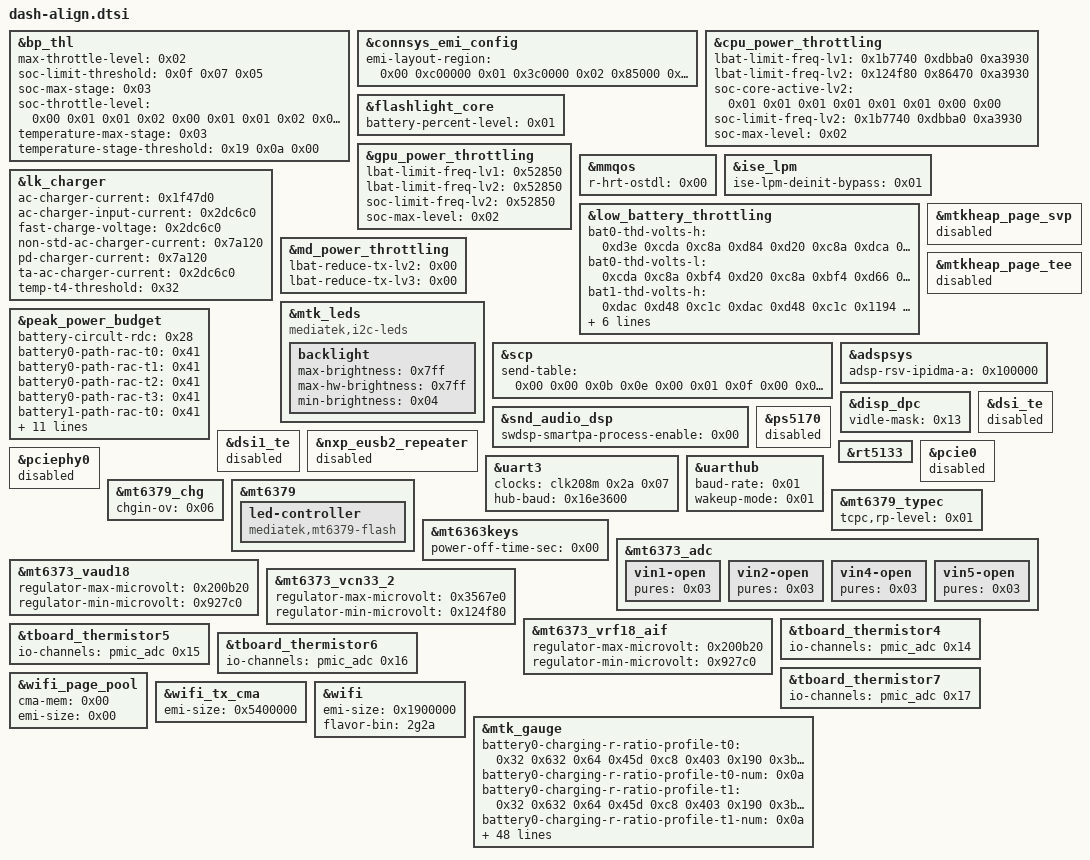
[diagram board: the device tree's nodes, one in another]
// SPDX-License-Identifier: (GPL-2.0 OR MIT)
/*
 * Pin the merged dash dtb to the values of the dtb the device is
 * proven to boot with (stock base, dtb/01_dtbdump_MT6991.dtb).
 * The xiaomi base and the reconstructed overlay carry the tuning of
 * a newer stock release; the drifting values below are aligned back.
 * Kept from the source: the dash-specific battery table, the newer
 * display event tables (supersets), and the connectivity/DRAM
 * identity (mt6639 wifi, current dram flavor).
 */

&bp_thl {
	max-throttle-level = <0x02>;
	soc-limit-threshold = <0x0f 0x07 0x05>;
	soc-max-stage = <0x03>;
	soc-throttle-level = <0x00 0x01 0x01 0x02 0x00 0x01 0x01 0x02 0x00 0x01 0x01 0x02 0x00 0x01 0x02 0x02>;
	temperature-max-stage = <0x03>;
	temperature-stage-threshold = <0x19 0x0a 0x00>;
};

&connsys_emi_config {
	emi-layout-region = <0x00 0xc00000 0x01 0x3c0000 0x02 0x85000 0x03 0x4b000 0x04 0x12000 0x05 0xe000 0x06 0x40000 0x07 0x140000 0x08 0x2fa000 0x09 0xd6000 0x0a 0xa0000 0x0b 0x1900000>;
};

&cpu_power_throttling {
	lbat-limit-freq-lv1 = <0x1b7740 0xdbba0 0xa3930>;
	lbat-limit-freq-lv2 = <0x124f80 0x86470 0xa3930>;
	soc-core-active-lv2 = <0x01 0x01 0x01 0x01 0x01 0x01 0x00 0x00>;
	soc-limit-freq-lv2 = <0x1b7740 0xdbba0 0xa3930>;
	soc-max-level = <0x02>;
};

&flashlight_core {
	battery-percent-level = <0x01>;
};

&gpu_power_throttling {
	lbat-limit-freq-lv1 = <0x52850>;
	lbat-limit-freq-lv2 = <0x52850>;
	soc-limit-freq-lv2 = <0x52850>;
	soc-max-level = <0x02>;
};

&mmqos {
	r-hrt-ostdl = <0x00>;
};

&ise_lpm {
	ise-lpm-deinit-bypass = <0x01>;
};

&lk_charger {
	ac-charger-current = <0x1f47d0>;
	ac-charger-input-current = <0x2dc6c0>;
	fast-charge-voltage = <0x2dc6c0>;
	non-std-ac-charger-current = <0x7a120>;
	pd-charger-current = <0x7a120>;
	ta-ac-charger-current = <0x2dc6c0>;
	temp-t4-threshold = <0x32>;
};

&low_battery_throttling {
	bat0-thd-volts-h = <0xd3e 0xcda 0xc8a 0xd84 0xd20 0xc8a 0xdca 0xd66 0xc8a 0xe38 0xdd4 0xc8a>;
	bat0-thd-volts-l = <0xcda 0xc8a 0xbf4 0xd20 0xc8a 0xbf4 0xd66 0xc8a 0xbf4 0xdd4 0xc8a 0xbf4>;
	bat1-thd-volts-h = <0xdac 0xd48 0xc1c 0xdac 0xd48 0xc1c 0x1194 0x1130 0xd48 0x1388 0x1324 0x12c0>;
	bat1-thd-volts-l = <0xd48 0xc1c 0xb54 0xd48 0xc1c 0xb54 0x1130 0xd48 0xc1c 0x1324 0x12c0 0x1130>;
	lvsys-thd-volt-h = <0xc1c>;
	temperature-stage-threshold = <0x19 0x0a 0x00>;
	throttle-level = <0x00 0x01 0x02 0x03 0x00 0x01 0x02 0x03 0x00 0x01 0x02 0x03 0x00 0x01 0x02 0x03>;
};

&md_power_throttling {
	lbat-reduce-tx-lv2 = <0x00>;
	lbat-reduce-tx-lv3 = <0x00>;
};

&mtk_leds {
	compatible = "mediatek,i2c-leds";
	backlight {
		max-brightness = <0x7ff>;
		max-hw-brightness = <0x7ff>;
		min-brightness = <0x04>;
	};
};

&mtkheap_page_svp {
	status = "disabled";
};

&mtkheap_page_tee {
	status = "disabled";
};

&peak_power_budget {
	battery-circult-rdc = <0x28>;
	battery0-path-rac-t0 = <0x41>;
	battery0-path-rac-t1 = <0x41>;
	battery0-path-rac-t2 = <0x41>;
	battery0-path-rac-t3 = <0x41>;
	battery1-path-rac-t0 = <0x41>;
	battery1-path-rac-t1 = <0x41>;
	battery1-path-rac-t2 = <0x41>;
	battery1-path-rac-t3 = <0x41>;
	battery2-path-rac-t0 = <0x41>;
	battery2-path-rac-t1 = <0x41>;
	battery2-path-rac-t2 = <0x41>;
	battery2-path-rac-t3 = <0x41>;
	soc-hpt-ctrl-lv2 = <0x00>;
	soc-max-level = <0x02>;
	system-uvlo = <0xa32>;
	temperature-threshold = <0x19 0x0a 0x00>;
};

&scp {
	send-table = <0x00 0x00 0x0b 0x0e 0x00 0x01 0x0f 0x00 0x02 0x10 0x00 0x01 0x12 0x00 0x02 0x2e 0x00 0x01 0x11 0x01 0x06 0x1d 0x01 0x10 0x1f 0x01 0x07 0x34 0x01 0x0a 0x04 0x02 0x01 0x05 0x02 0x02 0x06 0x02 0x01 0x21 0x02 0x10 0x36 0x02 0x04 0x03 0x03 0x04 0x25 0x03 0x01 0x1a 0x03 0x09 0x23 0x03 0x02 0x2d 0x03 0x01 0x2f 0x03 0x02 0x30 0x03 0x02 0x27 0x04 0x04 0x2b 0x04 0x04>;
};

&snd_audio_dsp {
	swdsp-smartpa-process-enable = <0x00>;
};

&adspsys {
	adsp-rsv-ipidma-a = <0x100000>;
};

&disp_dpc {
	vidle-mask = <0x13>;
};

&dsi_te {
	status = "disabled";
};

&dsi1_te {
	status = "disabled";
};

&nxp_eusb2_repeater {
	status = "disabled";
};

&ps5170 {
	status = "disabled";
};

&rt5133 {
	status = "ok";
};

&pcie0 {
	status = "disabled";
};

&pciephy0 {
	status = "disabled";
};

&uart3 {
	clocks = <&clk208m 0x2a 0x07>;
	hub-baud = <0x16e3600>;
};

&uarthub {
	baud-rate = <0x01>;
	wakeup-mode = <0x01>;
};

&mt6379_chg {
	chgin-ov = <0x06>;
};

&mt6379 {
	led-controller {
		compatible = "mediatek,mt6379-flash";
	};
};

&mt6379_typec {
	tcpc,rp-level = <0x01>;
};

&mt6363keys {
	power-off-time-sec = <0x00>;
};

&mt6373_adc {
	vin1-open {
		pures = <0x03>;
	};
	vin2-open {
		pures = <0x03>;
	};
	vin4-open {
		pures = <0x03>;
	};
	vin5-open {
		pures = <0x03>;
	};
};

&mt6373_vaud18 {
	regulator-max-microvolt = <0x200b20>;
	regulator-min-microvolt = <0x927c0>;
};

&mt6373_vcn33_2 {
	regulator-max-microvolt = <0x3567e0>;
	regulator-min-microvolt = <0x124f80>;
};

&mt6373_vrf18_aif {
	regulator-max-microvolt = <0x200b20>;
	regulator-min-microvolt = <0x927c0>;
};

&tboard_thermistor4 {
	io-channels = <&pmic_adc 0x14>;
};

&tboard_thermistor5 {
	io-channels = <&pmic_adc 0x15>;
};

&tboard_thermistor6 {
	io-channels = <&pmic_adc 0x16>;
};

&tboard_thermistor7 {
	io-channels = <&pmic_adc 0x17>;
};

&wifi_page_pool {
	cma-mem = <0x00>;
	emi-size = <0x00>;
};

&wifi_tx_cma {
	emi-size = <0x5400000>;
};

&wifi {
	emi-size = <0x1900000>;
	flavor-bin = "2g2a";
};

/* Battery: align the fuel gauge table with the proven dtb. The newer
 * dash table made the gauge report 0% (ui_soc=0) and the device shuts
 * down right after the logo. */
&mtk_gauge {
	battery0-charging-r-ratio-profile-t0 = <0x32 0x632 0x64 0x45d 0xc8 0x403 0x190 0x3bb 0x258 0x3a3 0x320 0x385 0x3e8 0x35d 0x5dc 0x336 0x7d0 0x332 0x9c4 0x2db>;
	battery0-charging-r-ratio-profile-t0-num = <0x0a>;
	battery0-charging-r-ratio-profile-t1 = <0x32 0x632 0x64 0x45d 0xc8 0x403 0x190 0x3bb 0x258 0x3a3 0x320 0x385 0x3e8 0x35d 0x5dc 0x336 0x7d0 0x332 0x9c4 0x2db>;
	battery0-charging-r-ratio-profile-t1-num = <0x0a>;
	battery0-charging-r-ratio-profile-t2 = <0x32 0x632 0x64 0x45d 0xc8 0x403 0x190 0x3bb 0x258 0x3a3 0x320 0x385 0x3e8 0x35d 0x5dc 0x336 0x7d0 0x332 0x9c4 0x2db>;
	battery0-charging-r-ratio-profile-t2-num = <0x0a>;
	battery0-charging-r-ratio-profile-t3 = <0x32 0x632 0x64 0x45d 0xc8 0x403 0x190 0x3bb 0x258 0x3a3 0x320 0x385 0x3e8 0x35d 0x5dc 0x336 0x7d0 0x332 0x9c4 0x2db>;
	battery0-charging-r-ratio-profile-t3-num = <0x0a>;
	battery0-charging-r-ratio-profile-t4 = <0x32 0x632 0x64 0x45d 0xc8 0x403 0x190 0x3bb 0x258 0x3a3 0x320 0x385 0x3e8 0x35d 0x5dc 0x336 0x7d0 0x332 0x9c4 0x2db>;
	battery0-charging-r-ratio-profile-t4-num = <0x0a>;
	battery0-profile-t0 = <0x00 0xa956 0x96 0x17c 0xa8f7 0x96 0x2f8 0xa886 0x96 0x473 0xa82e 0xd6 0x5ef 0xa790 0x69 0x76b 0xa738 0x106 0x8e7 0xa6bd 0xff 0xa63 0xa656 0xe1 0xbde 0xa5e9 0xc3 0xd5a 0xa578 0xaf 0xed6 0xa510 0xc8 0x1052 0xa4a7 0xec 0x11ce 0xa427 0xf0 0x1349 0xa3a8 0xe1 0x14c5 0xa348 0xda 0x1641 0xa2c1 0xd4 0x17bd 0xa27f 0xfa 0x1939 0xa20f 0xec 0x1ab4 0xa180 0x9f 0x1c30 0xa13c 0xfe 0x1dac 0xa0dd 0x15d 0x1f28 0xa046 0xe9 0x20a4 0xa007 0x10d 0x221f 0x9fb5 0x113 0x239b 0x9f20 0xc4 0x2517 0x9edf 0xf9 0x2693 0x9e8f 0x169 0x280f 0x9e37 0x150 0x298a 0x9dd6 0x167 0x2b06 0x9d72 0x183 0x2c82 0x9d05 0x13a 0x2dfe 0x9c9b 0x11b 0x2f7a 0x9c55 0x175 0x30f5 0x9c11 0x1c2 0x3271 0x9ba6 0x1a6 0x33ed 0x9b2d 0x14d 0x3569 0x9aa2 0x125 0x36e5 0x9a24 0x16a 0x3860 0x9999 0x107 0x39dc 0x9932 0x83 0x3b58 0x9903 0x141 0x3cd4 0x98c1 0xd1 0x3e50 0x987e 0xf4 0x3fcb 0x983c 0x123 0x4147 0x9801 0xf2 0x42c3 0x97ab 0x98 0x443f 0x9789 0xe3 0x45bb 0x9760 0xf4 0x4736 0x9727 0x11b 0x48b2 0x96df 0xe9 0x4a2e 0x96a1 0x96 0x4baa 0x9683 0xb8 0x4d25 0x9664 0xe1 0x4ea1 0x962a 0xc7 0x501d 0x95f6 0xd9 0x5199 0x95e7 0x158 0x5315 0x95aa 0xfa 0x5490 0x956b 0x10c 0x560c 0x956b 0x161 0x5788 0x951a 0x9c 0x5904 0x9524 0x112 0x5a80 0x94d8 0xcc 0x5bfb 0x94b9 0xc8 0x5d77 0x94be 0x171 0x5ef3 0x9471 0xde 0x606f 0x943e 0x11e 0x61eb 0x93e8 0xef 0x6366 0x93b3 0x128 0x64e2 0x936d 0xd9 0x665e 0x9339 0xc1 0x67da 0x9304 0xb1 0x6956 0x92d2 0xd2 0x6ad1 0x92a9 0x11a 0x6c4d 0x9261 0xc8 0x6dc9 0x9234 0xf3 0x6f45 0x9216 0xe1 0x70c1 0x91ff 0xd3 0x723c 0x91b7 0xa7 0x73b8 0x9185 0x102 0x7534 0x913b 0x51 0x76b0 0x9115 0xf7 0x782c 0x90e5 0xcb 0x79a7 0x90b6 0x14d 0x7b23 0x9044 0xb7 0x7c9f 0x9026 0x10b 0x7e1b 0x9015 0x13e 0x7f97 0x9009 0x156 0x8112 0x9000 0x11f 0x828e 0x8ff6 0x109 0x840a 0x8fcd 0x120 0x8586 0x8fa2 0xfc 0x8702 0x8f53 0xfe 0x887d 0x8e6c 0x13c 0x89f9 0x8cfc 0x12c 0x8b75 0x8b33 0x117 0x8cf1 0x88b9 0x11a 0x8e6d 0x8572 0x1d7 0x8fe8 0x7fd4 0x3e3 0x9164 0x7472 0x17b7 0x92e0 0x6e0a 0x327d>;
	battery0-profile-t0-col = <0x03>;
	battery0-profile-t0-num = <0x64>;
	battery0-profile-t1 = <0x00 0xa92e 0x1db 0x17c 0xa8a0 0x1db 0x2f8 0xa835 0x1db 0x473 0xa7cd 0x1f0 0x5ef 0xa74c 0x1cc 0x76b 0xa6cf 0x19d 0x8e7 0xa668 0x1c4 0xa63 0xa603 0x1eb 0xbde 0xa583 0x1aa 0xd5a 0xa520 0x1e4 0xed6 0xa4b6 0x20e 0x1052 0xa442 0x1fc 0x11ce 0xa3e1 0x21c 0x1349 0xa36b 0x216 0x14c5 0xa2f3 0x201 0x1641 0xa281 0x1b5 0x17bd 0xa211 0x1d6 0x1939 0xa1aa 0x1cd 0x1ab4 0xa14c 0x20f 0x1c30 0xa0f6 0x225 0x1dac 0xa08d 0x20d 0x1f28 0xa01b 0x23c 0x20a4 0x9fbb 0x23f 0x221f 0x9f5c 0x269 0x239b 0x9ef5 0x20f 0x2517 0x9e86 0x219 0x2693 0x9e28 0x248 0x280f 0x9dd3 0x258 0x298a 0x9d83 0x275 0x2b06 0x9d2c 0x28a 0x2c82 0x9cd7 0x2a2 0x2dfe 0x9c7e 0x2b1 0x2f7a 0x9c1a 0x2c0 0x30f5 0x9bb4 0x2dd 0x3271 0x9b42 0x2ae 0x33ed 0x9ac5 0x279 0x3569 0x9a2c 0x23f 0x36e5 0x99bc 0x235 0x3860 0x9956 0x1f6 0x39dc 0x990a 0x20e 0x3b58 0x98c7 0x225 0x3cd4 0x9872 0x1b2 0x3e50 0x981d 0x1a9 0x3fcb 0x97e0 0x1a9 0x4147 0x97a0 0x1bc 0x42c3 0x976c 0x1b0 0x443f 0x973c 0x1cb 0x45bb 0x970d 0x1cb 0x4736 0x96e3 0x1d0 0x48b2 0x96b2 0x1ce 0x4a2e 0x9688 0x1f1 0x4baa 0x965a 0x206 0x4d25 0x9627 0x1f7 0x4ea1 0x9607 0x23e 0x501d 0x95e1 0x24f 0x5199 0x95b9 0x1ff 0x5315 0x9588 0x219 0x5490 0x9555 0x1e7 0x560c 0x9548 0x23a 0x5788 0x9519 0x1f3 0x5904 0x94ea 0x1dc 0x5a80 0x94f1 0x265 0x5bfb 0x94be 0x25b 0x5d77 0x94ae 0x281 0x5ef3 0x9486 0x277 0x606f 0x944f 0x23b 0x61eb 0x941d 0x205 0x6366 0x9400 0x203 0x64e2 0x93d0 0x1f1 0x665e 0x939d 0x202 0x67da 0x9369 0x1ec 0x6956 0x9333 0x1b3 0x6ad1 0x9306 0x1cb 0x6c4d 0x92d0 0x1e3 0x6dc9 0x92a3 0x1f4 0x6f45 0x9280 0x1e4 0x70c1 0x9262 0x1bd 0x723c 0x923c 0x226 0x73b8 0x9213 0x220 0x7534 0x91c7 0x1c3 0x76b0 0x9198 0x20a 0x782c 0x9172 0x251 0x79a7 0x9118 0x1d7 0x7b23 0x90c1 0x1ea 0x7c9f 0x908a 0x1e1 0x7e1b 0x9085 0x210 0x7f97 0x9074 0x216 0x8112 0x9064 0x1ef 0x828e 0x9060 0x213 0x840a 0x904c 0x226 0x8586 0x901d 0x224 0x8702 0x8fb3 0x221 0x887d 0x8ebe 0x20f 0x89f9 0x8d2a 0x256 0x8b75 0x8b34 0x2b0 0x8cf1 0x88a8 0x307 0x8e6d 0x84b4 0x2dc 0x8fe8 0x7de0 0x87b 0x9164 0x6f46 0x2f73 0x92e0 0x6cc0 0x2f44>;
	battery0-profile-t1-col = <0x03>;
	battery0-profile-t1-num = <0x64>;
	battery0-profile-t2 = <0x00 0xa938 0x52d 0x17c 0xa8c6 0x52d 0x2f8 0xa85d 0x55a 0x473 0xa7ca 0x51f 0x5ef 0xa75a 0x53c 0x76b 0xa6e3 0x50e 0x8e7 0xa66e 0x4fb 0xa63 0xa5fc 0x4db 0xbde 0xa5a8 0x54f 0xd5a 0xa545 0x558 0xed6 0xa4cf 0x514 0x1052 0xa46a 0x535 0x11ce 0xa409 0x57d 0x1349 0xa390 0x590 0x14c5 0xa317 0x566 0x1641 0xa2ac 0x55a 0x17bd 0xa223 0x4f6 0x1939 0xa1b8 0x4f7 0x1ab4 0xa172 0x571 0x1c30 0xa10a 0x52c 0x1dac 0xa0a1 0x514 0x1f28 0xa042 0x52b 0x20a4 0x9fc0 0x501 0x221f 0x9f6d 0x525 0x239b 0x9f09 0x568 0x2517 0x9e92 0x509 0x2693 0x9e2b 0x504 0x280f 0x9ddf 0x524 0x298a 0x9d80 0x559 0x2b06 0x9d33 0x585 0x2c82 0x9cd3 0x56d 0x2dfe 0x9c68 0x55c 0x2f7a 0x9c1a 0x58b 0x30f5 0x9ba3 0x599 0x3271 0x9b0d 0x547 0x33ed 0x9a92 0x4bd 0x3569 0x9a1e 0x497 0x36e5 0x99c7 0x49a 0x3860 0x9965 0x4aa 0x39dc 0x98e3 0x469 0x3b58 0x98c7 0x4df 0x3cd4 0x984d 0x3e2 0x3e50 0x9806 0x3fb 0x3fcb 0x97ed 0x4a7 0x4147 0x979c 0x42d 0x42c3 0x9753 0x3dd 0x443f 0x9717 0x424 0x45bb 0x96fe 0x49a 0x4736 0x96d2 0x456 0x48b2 0x968a 0x428 0x4a2e 0x9651 0x440 0x4baa 0x9638 0x448 0x4d25 0x960d 0x465 0x4ea1 0x95cb 0x46d 0x501d 0x95b1 0x463 0x5199 0x9573 0x414 0x5315 0x9549 0x41b 0x5490 0x9538 0x4a6 0x560c 0x9534 0x510 0x5788 0x9505 0x4df 0x5904 0x94cc 0x469 0x5a80 0x94b8 0x4c1 0x5bfb 0x948b 0x447 0x5d77 0x9484 0x4ae 0x5ef3 0x9475 0x516 0x606f 0x942f 0x49e 0x61eb 0x9402 0x465 0x6366 0x93f8 0x484 0x64e2 0x93d0 0x4a5 0x665e 0x9398 0x489 0x67da 0x9385 0x4b6 0x6956 0x9371 0x4e0 0x6ad1 0x933c 0x485 0x6c4d 0x9306 0x455 0x6dc9 0x92d6 0x46e 0x6f45 0x92c5 0x4f4 0x70c1 0x9283 0x48e 0x723c 0x926e 0x4e5 0x73b8 0x9245 0x4f5 0x7534 0x91ef 0x498 0x76b0 0x91a3 0x4c7 0x782c 0x9173 0x485 0x79a7 0x913a 0x493 0x7b23 0x90f9 0x4bf 0x7c9f 0x90a8 0x4c9 0x7e1b 0x908b 0x4db 0x7f97 0x906e 0x4e2 0x8112 0x905a 0x4f1 0x828e 0x905c 0x56a 0x840a 0x9056 0x5d0 0x8586 0x902c 0x5f3 0x8702 0x8fea 0x65f 0x887d 0x8f41 0x6bb 0x89f9 0x8dc4 0x693 0x8b75 0x8bd4 0x6d7 0x8cf1 0x8962 0x7c2 0x8e6d 0x8605 0x9a5 0x8fe8 0x806d 0x11d0 0x9164 0x73ae 0x3e47 0x92e0 0x7102 0x3a1b>;
	battery0-profile-t2-col = <0x03>;
	battery0-profile-t2-num = <0x64>;
	battery0-profile-t3 = <0x00 0xa94c 0xaf0 0x17c 0xa900 0xaf0 0x2f8 0xa851 0xa96 0x473 0xa803 0xa62 0x5ef 0xa778 0xa5a 0x76b 0xa6fe 0xa0f 0x8e7 0xa6af 0xa93 0xa63 0xa653 0xad7 0xbde 0xa5c7 0xa60 0xd5a 0xa556 0xa61 0xed6 0xa4fc 0xabe 0x1052 0xa474 0xa73 0x11ce 0xa3e9 0x9e2 0x1349 0xa394 0xa11 0x14c5 0xa340 0xa96 0x1641 0xa2c9 0xa5b 0x17bd 0xa263 0xa2c 0x1939 0xa201 0xa90 0x1ab4 0xa18b 0xa01 0x1c30 0xa0ee 0x984 0x1dac 0xa0b5 0xa89 0x1f28 0xa04d 0xa75 0x20a4 0x9fc1 0xa30 0x221f 0x9f5c 0x9fe 0x239b 0x9efd 0x9a7 0x2517 0x9ebc 0xa13 0x2693 0x9e45 0xa1f 0x280f 0x9de9 0xa5f 0x298a 0x9da1 0xab8 0x2b06 0x9d30 0xa44 0x2c82 0x9cc3 0xa31 0x2dfe 0x9c5d 0xa38 0x2f7a 0x9be0 0x9e5 0x30f5 0x9b7b 0xa28 0x3271 0x9b21 0xa0b 0x33ed 0x9a9a 0x9fb 0x3569 0x99fa 0x907 0x36e5 0x9990 0x8e4 0x3860 0x9953 0x985 0x39dc 0x98c5 0x8b3 0x3b58 0x98a9 0x8fa 0x3cd4 0x9856 0x8e5 0x3e50 0x9811 0x93b 0x3fcb 0x97bd 0x932 0x4147 0x9771 0x941 0x42c3 0x9750 0x912 0x443f 0x9702 0x8ec 0x45bb 0x96e2 0x96a 0x4736 0x96a9 0x92d 0x48b2 0x967d 0x958 0x4a2e 0x966a 0x9f6 0x4baa 0x9622 0x9b8 0x4d25 0x95d1 0x957 0x4ea1 0x95b3 0x97b 0x501d 0x95ab 0x9dd 0x5199 0x9578 0x9a1 0x5315 0x9554 0x9d9 0x5490 0x9511 0x9d0 0x560c 0x9518 0xa42 0x5788 0x94f2 0xa5a 0x5904 0x94b9 0x99d 0x5a80 0x9480 0x9d5 0x5bfb 0x9482 0x9dd 0x5d77 0x944c 0x9c9 0x5ef3 0x9445 0xa0e 0x606f 0x9433 0xa90 0x61eb 0x93fd 0xa8e 0x6366 0x93d2 0xa1a 0x64e2 0x93cb 0xa2e 0x665e 0x93b3 0xa42 0x67da 0x9387 0xa30 0x6956 0x935f 0xa6d 0x6ad1 0x933d 0xa9d 0x6c4d 0x932d 0xab0 0x6dc9 0x92e8 0xa92 0x6f45 0x92c2 0xaca 0x70c1 0x92bd 0xb77 0x723c 0x9291 0xbba 0x73b8 0x922a 0xbd5 0x7534 0x91fb 0xc4c 0x76b0 0x91af 0xc1f 0x782c 0x91a1 0xcf9 0x79a7 0x914d 0xd01 0x7b23 0x911d 0xdd4 0x7c9f 0x90c3 0xe7e 0x7e1b 0x9092 0xf62 0x7f97 0x9055 0x1008 0x8112 0x9038 0x1101 0x828e 0x9028 0x11fe 0x840a 0x8ff8 0x1310 0x8586 0x8fb6 0x14b5 0x8702 0x8f70 0x1735 0x887d 0x8ef6 0x1aff 0x89f9 0x8ded 0x20b8 0x8b75 0x8c38 0x2bd1 0x8cf1 0x89d6 0x45a0 0x8e6d 0x871e 0x712f 0x8fe8 0x871e 0x712f 0x9164 0x871e 0x712f 0x92e0 0x871e 0x712f>;
	battery0-profile-t3-col = <0x03>;
	battery0-profile-t3-num = <0x64>;
	battery0-profile-t4 = <0x00 0xa974 0x1644 0x17c 0xa90c 0x1644 0x2f8 0xa86d 0x1687 0x473 0xa7dd 0x168f 0x5ef 0xa77e 0x1707 0x76b 0xa6d7 0x16a2 0x8e7 0xa650 0x15c8 0xa63 0xa5f8 0x162e 0xbde 0xa59a 0x1636 0xd5a 0xa50c 0x159a 0xed6 0xa484 0x15b9 0x1052 0xa431 0x164c 0x11ce 0xa3ed 0x1694 0x1349 0xa38d 0x16b8 0x14c5 0xa315 0x1657 0x1641 0xa289 0x1589 0x17bd 0xa202 0x1568 0x1939 0xa1d2 0x1580 0x1ab4 0xa13b 0x158e 0x1c30 0xa0fc 0x1547 0x1dac 0xa048 0x1500 0x1f28 0x9fdf 0x14a1 0x20a4 0x9f79 0x14f2 0x221f 0x9f19 0x14d6 0x239b 0x9ee0 0x152c 0x2517 0x9e5b 0x14cd 0x2693 0x9e16 0x1562 0x280f 0x9dc9 0x15f5 0x298a 0x9d60 0x1594 0x2b06 0x9cee 0x1517 0x2c82 0x9c6e 0x152d 0x2dfe 0x9be9 0x14d4 0x2f7a 0x9b7d 0x144d 0x30f5 0x9b28 0x14e4 0x3271 0x9ab2 0x14d8 0x33ed 0x9a39 0x140e 0x3569 0x99a0 0x1406 0x36e5 0x9989 0x14f3 0x3860 0x9906 0x13c1 0x39dc 0x989e 0x1438 0x3b58 0x9881 0x14de 0x3cd4 0x97e6 0x13a9 0x3e50 0x9792 0x13dd 0x3fcb 0x9756 0x1374 0x4147 0x9724 0x1425 0x42c3 0x9718 0x14e4 0x443f 0x96e4 0x1475 0x45bb 0x96a4 0x1478 0x4736 0x965a 0x142a 0x48b2 0x9623 0x13f9 0x4a2e 0x95f5 0x1459 0x4baa 0x95ca 0x148c 0x4d25 0x95ba 0x14ac 0x4ea1 0x9588 0x14d4 0x501d 0x9542 0x14ec 0x5199 0x9534 0x1513 0x5315 0x94f5 0x1563 0x5490 0x94c5 0x1559 0x560c 0x9498 0x1507 0x5788 0x948e 0x15ad 0x5904 0x9455 0x15dd 0x5a80 0x9437 0x15b3 0x5bfb 0x9456 0x1642 0x5d77 0x9464 0x1723 0x5ef3 0x93fe 0x1678 0x606f 0x9404 0x16d8 0x61eb 0x9409 0x1785 0x6366 0x93c1 0x1771 0x64e2 0x938f 0x17d3 0x665e 0x9399 0x1882 0x67da 0x9385 0x1902 0x6956 0x933d 0x196e 0x6ad1 0x931c 0x19f4 0x6c4d 0x9316 0x1ac5 0x6dc9 0x92ca 0x1aa8 0x6f45 0x92a4 0x1b3a 0x70c1 0x9295 0x1c6e 0x723c 0x9231 0x1c95 0x73b8 0x91f9 0x1d5f 0x7534 0x91dc 0x1f51 0x76b0 0x91c0 0x2014 0x782c 0x9192 0x2183 0x79a7 0x9139 0x22ab 0x7b23 0x90c2 0x238d 0x7c9f 0x9097 0x259a 0x7e1b 0x904e 0x278c 0x7f97 0x902e 0x2aaa 0x8112 0x9000 0x2e03 0x828e 0x8fc9 0x3244 0x840a 0x8fac 0x38c5 0x8586 0x8f91 0x42bd 0x8702 0x8f41 0x5492 0x887d 0x8ec6 0x7288 0x89f9 0x8e9e 0x846c 0x8b75 0x8e9e 0x846c 0x8cf1 0x8e9e 0x846c 0x8e6d 0x8e9e 0x846c 0x8fe8 0x8e9e 0x846c 0x9164 0x8e9e 0x846c 0x92e0 0x8e9e 0x846c>;
	battery0-profile-t4-col = <0x03>;
	battery0-profile-t4-num = <0x64>;
	battery0-r-ratio-profile-t0 = <0x32 0x541 0x64 0x4ba 0xc8 0x455 0x190 0x3e8 0x258 0x3be 0x320 0x3b1 0x3e8 0x37e 0x5dc 0x351 0x7d0 0x311 0x9c4 0x30c 0xbb8 0x30a>;
	battery0-r-ratio-profile-t0-num = <0x0b>;
	battery0-r-ratio-profile-t1 = <0x32 0x541 0x64 0x4ba 0xc8 0x455 0x190 0x3e8 0x258 0x3be 0x320 0x3b1 0x3e8 0x37e 0x5dc 0x351 0x7d0 0x311 0x9c4 0x30c 0xbb8 0x30a>;
	battery0-r-ratio-profile-t1-num = <0x0b>;
	battery0-r-ratio-profile-t2 = <0x32 0x541 0x64 0x4ba 0xc8 0x455 0x190 0x3e8 0x258 0x3be 0x320 0x3b1 0x3e8 0x37e 0x5dc 0x351 0x7d0 0x311 0x9c4 0x30c 0xbb8 0x30a>;
	battery0-r-ratio-profile-t2-num = <0x0b>;
	battery0-r-ratio-profile-t3 = <0x32 0x483 0x64 0x435 0xc8 0x429 0x190 0x3e8 0x258 0x3ba 0x320 0x37f 0x3e8 0x356 0x5dc 0x309 0x7d0 0x2d1 0x9c4 0x2d1 0xbb8 0x2d1>;
	battery0-r-ratio-profile-t3-num = <0x0b>;
	battery0-r-ratio-profile-t4 = <0x32 0x483 0x64 0x435 0xc8 0x429 0x190 0x3e8 0x258 0x3ba 0x320 0x37f 0x3e8 0x356 0x5dc 0x309 0x7d0 0x2d1 0x9c4 0x2d1 0xbb8 0x2d1>;
	battery0-r-ratio-profile-t4-num = <0x0b>;
	g-pmic-min-vol = <0x884a 0x884a 0x884a 0x884a 0x884a 0x884a 0x884a 0x884a 0x884a 0x884a 0x884a 0x884a 0x8340 0x8340 0x8340 0x8340 0x841c 0x841c 0x841c 0x841c 0x7b0c 0x7b0c 0x7b0c 0x7b0c 0x7918 0x7918 0x7918 0x7918 0x7918 0x7918 0x7918 0x7918 0x7918 0x7918 0x7918 0x7918 0x7918 0x7918 0x7918 0x79e0>;
	g-qmax-sys-vol = <0x8980 0x8980 0x8980 0x8980 0x8980 0x8980 0x8980 0x8980 0x8980 0x8980 0x8980 0x8980 0x7918 0x7918 0x7918 0x7918 0x7918 0x7918 0x7918 0x7918 0x7ef4 0x7ef4 0x7ef4 0x7ef4 0x8020 0x8020 0x8020 0x8020 0x8020 0x8020 0x8020 0x8020 0x8020 0x8020 0x8020 0x8020 0x8020 0x8020 0x8020 0x8020>;
};
